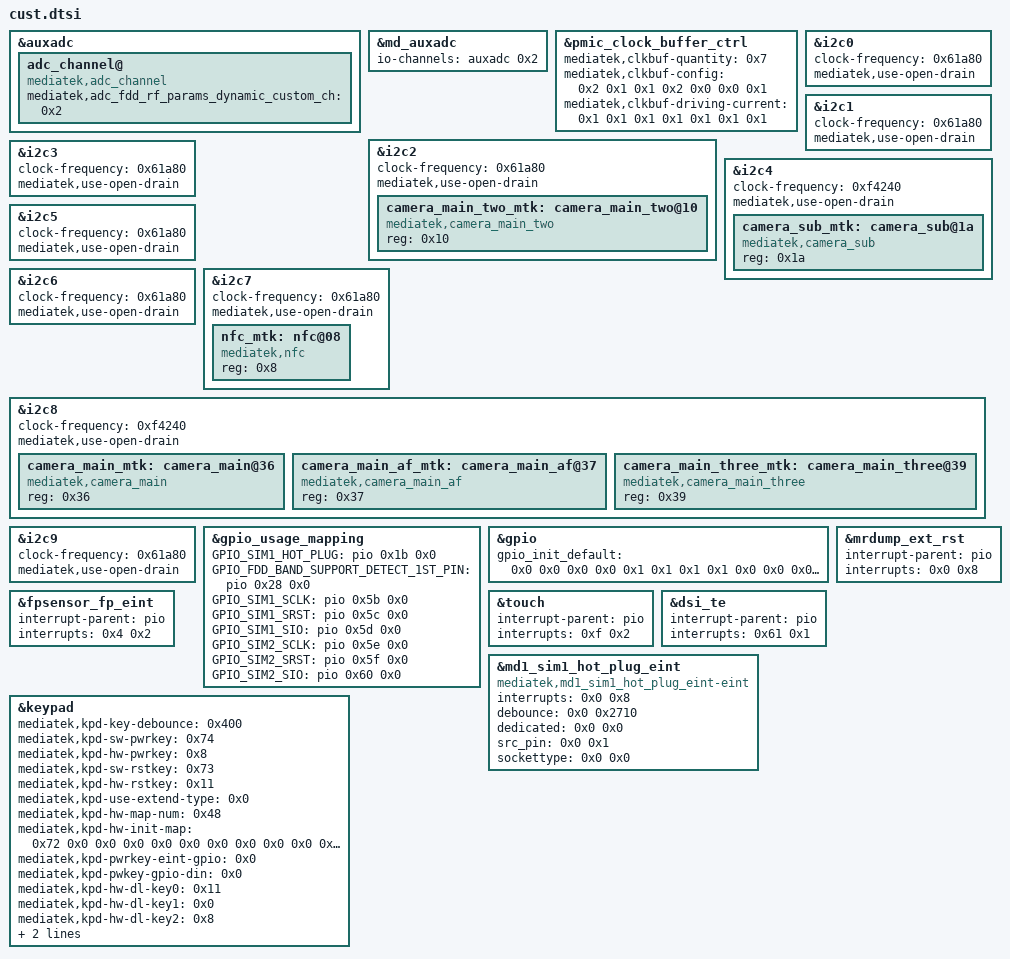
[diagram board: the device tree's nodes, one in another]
// SPDX-License-Identifier: GPL-2.0-only
/* Redmi Note 12S (sea / mt6781) DCT Custom Peripheral & EINT/I2C/GPIO Pinmux bindings for Kernel 6.6 */

&auxadc {
    adc_channel@ {
        compatible = "mediatek,adc_channel";
        mediatek,adc_fdd_rf_params_dynamic_custom_ch = <0x2>;
        status = "okay";
    };
};

&md_auxadc {
    io-channels = <&auxadc 0x2>;
};

&pmic_clock_buffer_ctrl {
    mediatek,clkbuf-quantity = <0x7>;
    mediatek,clkbuf-config = <0x2 0x1 0x1 0x2 0x0 0x0 0x1>;
    mediatek,clkbuf-driving-current = <0x1 0x1 0x1 0x1 0x1 0x1 0x1>;
    status = "okay";
};

&i2c0 {
    #address-cells = <0x1>;
    #size-cells = <0x0>;
    clock-frequency = <0x61a80>;
    mediatek,use-open-drain;
};

&i2c1 {
    #address-cells = <0x1>;
    #size-cells = <0x0>;
    clock-frequency = <0x61a80>;
    mediatek,use-open-drain;
};

&i2c2 {
    #address-cells = <0x1>;
    #size-cells = <0x0>;
    clock-frequency = <0x61a80>;
    mediatek,use-open-drain;
    camera_main_two_mtk: camera_main_two@10 {
        compatible = "mediatek,camera_main_two";
        reg = <0x10>;
        status = "okay";
    };
};

&i2c3 {
    #address-cells = <0x1>;
    #size-cells = <0x0>;
    clock-frequency = <0x61a80>;
    mediatek,use-open-drain;
};

&i2c4 {
    #address-cells = <0x1>;
    #size-cells = <0x0>;
    clock-frequency = <0xf4240>;
    mediatek,use-open-drain;
    camera_sub_mtk: camera_sub@1a {
        compatible = "mediatek,camera_sub";
        reg = <0x1a>;
        status = "okay";
    };
};

&i2c5 {
    #address-cells = <0x1>;
    #size-cells = <0x0>;
    clock-frequency = <0x61a80>;
    mediatek,use-open-drain;
};

&i2c6 {
    #address-cells = <0x1>;
    #size-cells = <0x0>;
    clock-frequency = <0x61a80>;
    mediatek,use-open-drain;
};

&i2c7 {
    #address-cells = <0x1>;
    #size-cells = <0x0>;
    clock-frequency = <0x61a80>;
    mediatek,use-open-drain;
    nfc_mtk: nfc@08 {
        compatible = "mediatek,nfc";
        reg = <0x8>;
        status = "okay";
    };
};

&i2c8 {
    #address-cells = <0x1>;
    #size-cells = <0x0>;
    clock-frequency = <0xf4240>;
    mediatek,use-open-drain;
    camera_main_mtk: camera_main@36 {
        compatible = "mediatek,camera_main";
        reg = <0x36>;
        status = "okay";
    };
    camera_main_af_mtk: camera_main_af@37 {
        compatible = "mediatek,camera_main_af";
        reg = <0x37>;
        status = "okay";
    };
    camera_main_three_mtk: camera_main_three@39 {
        compatible = "mediatek,camera_main_three";
        reg = <0x39>;
        status = "okay";
    };
};

&i2c9 {
    #address-cells = <0x1>;
    #size-cells = <0x0>;
    clock-frequency = <0x61a80>;
    mediatek,use-open-drain;
};

&gpio_usage_mapping {
    GPIO_SIM1_HOT_PLUG = <&pio 0x1b 0x0>;
    GPIO_FDD_BAND_SUPPORT_DETECT_1ST_PIN = <&pio 0x28 0x0>;
    GPIO_SIM1_SCLK = <&pio 0x5b 0x0>;
    GPIO_SIM1_SRST = <&pio 0x5c 0x0>;
    GPIO_SIM1_SIO = <&pio 0x5d 0x0>;
    GPIO_SIM2_SCLK = <&pio 0x5e 0x0>;
    GPIO_SIM2_SRST = <&pio 0x5f 0x0>;
    GPIO_SIM2_SIO = <&pio 0x60 0x0>;
};

&gpio {
    gpio_init_default = <0x0 0x0 0x0 0x0 0x1 0x1 0x1 0x1 0x0 0x0 0x0 0x1 0x0 0x1 0x2 0x0 0x0 0x0 0x1 0x0 0x1 0x3 0x0 0x1 0x0 0x1 0x0 0x1 0x4 0x0 0x0 0x0 0x1 0x1 0x1 0x5 0x0 0x0 0x0 0x1 0x0 0x1 0x6 0x0 0x0 0x0 0x1 0x1 0x1 0x7 0x0 0x1 0x0 0x1 0x0 0x0 0x8 0x0 0x1 0x0 0x1 0x0 0x1 0x9 0x0 0x0 0x0 0x1 0x1 0x1 0xa 0x0 0x0 0x0 0x1 0x0 0x1 0xb 0x0 0x0 0x0 0x1 0x1 0x1 0xc 0x0 0x0 0x0 0x1 0x0 0x1 0xd 0x2 0x0 0x0 0x0 0x0 0x0 0xe 0x0 0x0 0x0 0x1 0x1 0x1 0xf 0x0 0x0 0x0 0x1 0x1 0x1 0x10 0x0 0x1 0x0 0x1 0x0 0x1 0x11 0x0 0x0 0x0 0x1 0x0 0x0 0x12 0x0 0x1 0x0 0x1 0x0 0x0 0x13 0x0 0x1 0x0 0x1 0x0 0x0 0x14 0x0 0x1 0x0 0x1 0x0 0x0 0x15 0x0 0x1 0x1 0x1 0x0 0x0 0x16 0x0 0x1 0x0 0x1 0x0 0x0 0x17 0x0 0x1 0x0 0x1 0x0 0x0 0x18 0x0 0x1 0x0 0x1 0x0 0x0 0x19 0x0 0x1 0x0 0x1 0x0 0x0 0x1a 0x0 0x1 0x0 0x1 0x0 0x0 0x1b 0x1 0x0 0x0 0x1 0x1 0x0 0x1c 0x0 0x0 0x0 0x1 0x0 0x0 0x1d 0x0 0x1 0x0 0x1 0x0 0x0 0x1e 0x0 0x1 0x0 0x1 0x0 0x0 0x1f 0x0 0x0 0x0 0x1 0x0 0x1 0x20 0x1 0x0 0x0 0x1 0x1 0x0 0x21 0x1 0x0 0x0 0x0 0x0 0x0 0x22 0x1 0x0 0x0 0x1 0x1 0x1 0x23 0x1 0x0 0x0 0x0 0x0 0x1 0x24 0x1 0x0 0x0 0x0 0x0 0x0 0x25 0x1 0x0 0x0 0x0 0x0 0x0 0x26 0x1 0x0 0x0 0x0 0x0 0x0 0x27 0x1 0x0 0x0 0x1 0x0 0x0 0x28 0x0 0x0 0x0 0x0 0x0 0x0 0x29 0x0 0x1 0x0 0x1 0x0 0x0 0x2a 0x1 0x0 0x0 0x0 0x0 0x0 0x2b 0x1 0x0 0x0 0x1 0x0 0x0 0x2c 0x2 0x0 0x0 0x0 0x0 0x0 0x2d 0x2 0x0 0x0 0x0 0x0 0x1 0x2e 0x2 0x0 0x0 0x0 0x0 0x0 0x2f 0x2 0x0 0x0 0x1 0x0 0x1 0x30 0x4 0x0 0x0 0x1 0x1 0x0 0x31 0x4 0x0 0x0 0x0 0x0 0x0 0x32 0x1 0x0 0x0 0x0 0x0 0x0 0x33 0x4 0x0 0x0 0x0 0x0 0x0 0x34 0x6 0x0 0x0 0x1 0x0 0x0 0x35 0x6 0x0 0x0 0x1 0x0 0x0 0x36 0x6 0x0 0x0 0x0 0x0 0x0 0x37 0x6 0x0 0x0 0x1 0x0 0x0 0x38 0x0 0x1 0x0 0x1 0x0 0x0 0x39 0x2 0x0 0x0 0x0 0x0 0x1 0x3a 0x2 0x0 0x0 0x0 0x0 0x1 0x3b 0x2 0x0 0x0 0x1 0x0 0x1 0x3c 0x3 0x0 0x0 0x1 0x0 0x0 0x3d 0x6 0x0 0x0 0x1 0x0 0x0 0x3e 0x6 0x0 0x0 0x1 0x1 0x0 0x3f 0x6 0x0 0x0 0x1 0x0 0x0 0x40 0x6 0x0 0x0 0x1 0x0 0x0 0x41 0x6 0x0 0x0 0x1 0x0 0x0 0x42 0x6 0x0 0x0 0x1 0x0 0x0 0x43 0x6 0x0 0x0 0x1 0x0 0x0 0x50 0x1 0x0 0x0 0x1 0x1 0x1 0x51 0x0 0x1 0x0 0x1 0x0 0x1 0x52 0x3 0x0 0x0 0x1 0x0 0x1 0x53 0x0 0x0 0x0 0x1 0x1 0x1 0x55 0x1 0x0 0x0 0x1 0x0 0x1 0x56 0x1 0x0 0x0 0x1 0x0 0x1 0x57 0x1 0x0 0x0 0x1 0x0 0x1 0x58 0x1 0x0 0x0 0x1 0x0 0x1 0x59 0x1 0x0 0x0 0x1 0x0 0x1 0x5a 0x1 0x0 0x0 0x1 0x0 0x1 0x5b 0x1 0x0 0x0 0x0 0x0 0x1 0x5c 0x1 0x0 0x0 0x0 0x0 0x1 0x5d 0x1 0x0 0x0 0x1 0x1 0x1 0x5e 0x1 0x0 0x0 0x0 0x0 0x1 0x5f 0x1 0x0 0x0 0x0 0x0 0x1 0x60 0x1 0x0 0x0 0x1 0x1 0x1 0x61 0x1 0x0 0x0 0x1 0x0 0x0 0x62 0x0 0x1 0x0 0x1 0x0 0x0 0x63 0x1 0x0 0x0 0x0 0x0 0x0 0x64 0x1 0x0 0x0 0x1 0x0 0x0 0x65 0x1 0x0 0x0 0x1 0x0 0x0 0x66 0x1 0x0 0x0 0x1 0x0 0x0 0x67 0x1 0x0 0x0 0x1 0x0 0x0 0x68 0x1 0x0 0x0 0x1 0x0 0x0 0x69 0x1 0x0 0x0 0x1 0x0 0x0 0x6a 0x1 0x0 0x0 0x1 0x0 0x0 0x6b 0x1 0x0 0x0 0x1 0x0 0x0 0x6c 0x1 0x0 0x0 0x1 0x0 0x1 0x6d 0x1 0x0 0x0 0x1 0x0 0x1 0x6e 0x1 0x0 0x0 0x1 0x0 0x1 0x6f 0x1 0x0 0x0 0x1 0x0 0x1 0x70 0x1 0x0 0x0 0x1 0x0 0x1 0x71 0x1 0x0 0x0 0x1 0x0 0x1 0x72 0x1 0x0 0x0 0x1 0x0 0x1 0x73 0x1 0x0 0x0 0x1 0x0 0x1 0x74 0x1 0x0 0x0 0x1 0x0 0x1 0x75 0x1 0x0 0x0 0x1 0x0 0x0 0x76 0x1 0x0 0x0 0x1 0x0 0x0 0x77 0x1 0x0 0x0 0x1 0x0 0x0 0x78 0x1 0x0 0x0 0x1 0x0 0x0 0x79 0x1 0x0 0x0 0x1 0x0 0x1 0x7a 0x1 0x0 0x0 0x1 0x0 0x1 0x7b 0x1 0x0 0x0 0x1 0x0 0x1 0x7c 0x1 0x0 0x0 0x1 0x0 0x0 0x7d 0x1 0x0 0x0 0x1 0x0 0x1 0x7e 0x1 0x0 0x0 0x1 0x0 0x0 0x7f 0x1 0x0 0x0 0x1 0x0 0x0 0x80 0x1 0x0 0x0 0x1 0x0 0x0 0x81 0x1 0x0 0x0 0x1 0x0 0x0 0x82 0x1 0x0 0x0 0x1 0x0 0x0 0x83 0x1 0x0 0x0 0x1 0x0 0x0 0x84 0x1 0x0 0x0 0x1 0x0 0x0 0x85 0x1 0x0 0x0 0x1 0x0 0x0 0x86 0x1 0x0 0x0 0x1 0x0 0x0 0x87 0x1 0x0 0x0 0x1 0x0 0x0 0x88 0x1 0x0 0x0 0x1 0x0 0x0 0x89 0x1 0x0 0x0 0x1 0x0 0x0 0x8a 0x1 0x0 0x0 0x1 0x0 0x0 0x8b 0x1 0x0 0x0 0x1 0x0 0x0 0x8c 0x1 0x0 0x0 0x1 0x0 0x0 0x8d 0x1 0x0 0x0 0x1 0x0 0x0 0x8e 0x1 0x0 0x0 0x1 0x0 0x0 0x8f 0x1 0x0 0x0 0x1 0x0 0x0 0x90 0x1 0x0 0x0 0x1 0x1 0x1 0x91 0x1 0x0 0x0 0x1 0x1 0x1 0x92 0x2 0x0 0x0 0x1 0x1 0x1 0x93 0x2 0x0 0x0 0x1 0x1 0x1 0x94 0x1 0x0 0x0 0x1 0x1 0x1 0x95 0x1 0x0 0x0 0x1 0x1 0x1 0x96 0x3 0x0 0x0 0x1 0x1 0x1 0x97 0x3 0x0 0x0 0x1 0x1 0x1 0x98 0x1 0x0 0x0 0x1 0x1 0x1 0x99 0x1 0x0 0x0 0x1 0x1 0x1 0x9a 0x1 0x0 0x0 0x1 0x1 0x1 0x9b 0x1 0x0 0x0 0x1 0x1 0x1 0x9c 0x1 0x0 0x0 0x1 0x1 0x1 0x9d 0x1 0x0 0x0 0x1 0x1 0x1 0x9e 0x1 0x0 0x0 0x1 0x1 0x1 0x9f 0x1 0x0 0x0 0x1 0x1 0x1 0xa0 0x1 0x0 0x0 0x1 0x1 0x1 0xa1 0x1 0x0 0x0 0x1 0x1 0x1 0xa2 0x1 0x0 0x0 0x1 0x1 0x1 0xa3 0x1 0x0 0x0 0x1 0x1 0x1 0xa4 0x0 0x1 0x1 0x1 0x0 0x1 0xa5 0x0 0x1 0x1 0x1 0x0 0x1 0xa6 0x0 0x1 0x0 0x1 0x0 0x1 0xa7 0x0 0x1 0x0 0x1 0x0 0x1 0xa8 0x0 0x1 0x0 0x1 0x0 0x1 0xa9 0x0 0x1 0x0 0x1 0x0 0x1 0xaa 0x0 0x1 0x0 0x1 0x0 0x1 0xab 0x0 0x1 0x0 0x1 0x0 0x1 0xac 0x2 0x0 0x0 0x1 0x0 0x1 0xad 0x2 0x0 0x0 0x1 0x0 0x1 0xae 0x1 0x0 0x0 0x0 0x0 0x1 0xaf 0x1 0x0 0x0 0x0 0x0 0x1 0xb0 0x1 0x0 0x0 0x1 0x0 0x1 0xb1 0x1 0x0 0x0 0x1 0x0 0x1 0xb2 0x1 0x0 0x0 0x0 0x0 0x0 0xb3 0x1 0x0 0x0 0x0 0x0 0x0 0xb4 0x1 0x0 0x0 0x0 0x0 0x1 0xb5 0x1 0x0 0x0 0x1 0x0 0x1 0xb6 0x1 0x0 0x0 0x0 0x0 0x0 0xb7 0x1 0x0 0x0 0x0 0x0 0x1 0xb8 0x1 0x0 0x0 0x0 0x0 0x1 0xb9 0x1 0x0 0x0 0x0 0x0 0x1 0xba 0x1 0x0 0x0 0x0 0x0 0x1 0xbb 0x1 0x0 0x0 0x1 0x0 0x1 0xbc 0x1 0x0 0x0 0x1 0x0 0x1 0xbd 0x1 0x0 0x0 0x1 0x0 0x1 0xbe 0x1 0x0 0x0 0x1 0x0 0x1 0xbf 0x0 0x0 0x0 0x1 0x0 0x0 0xc0 0x0 0x0 0x0 0x1 0x0 0x0 0xc1 0x0 0x0 0x0 0x1 0x0 0x0 0xc2 0x0 0x0 0x0 0x1 0x0 0x0 0xc3 0x0 0x0 0x0 0x1 0x0 0x0 0xc4 0x0 0x0 0x0 0x1 0x0 0x0 0xc5 0x0 0x0 0x0 0x1 0x0 0x0 0xc6 0x0 0x0 0x0 0x1 0x0 0x0 0xc7 0x0 0x0 0x0 0x1 0x0 0x0 0xc8 0x0 0x0 0x0 0x1 0x0 0x0 0xc9 0x0 0x0 0x0 0x1 0x0 0x0 0xca 0x0 0x0 0x0 0x1 0x0 0x0 0xcb 0x0 0x0 0x0 0x1 0x0 0x0 0xcc 0x0 0x0 0x0 0x1 0x0 0x0 0xcd 0x0 0x0 0x0 0x1 0x0 0x0 0xce 0x0 0x0 0x0 0x1 0x0 0x0 0xcf 0x0 0x0 0x0 0x1 0x0 0x0 0xd0 0x0 0x0 0x0 0x1 0x0 0x0 0xd1 0x0 0x0 0x0 0x1 0x0 0x0 0xd2 0x0 0x0 0x0 0x1 0x0 0x0 0xd3 0x0 0x0 0x0 0x1 0x0 0x0 0xd4 0x0 0x0 0x0 0x1 0x0 0x0 0xd5 0x0 0x0 0x0 0x1 0x0 0x0 0xd6 0x0 0x0 0x0 0x1 0x0 0x0 0xd7 0x0 0x0 0x0 0x1 0x0 0x0 0xd8 0x0 0x0 0x0 0x1 0x0 0x0 0xd9 0x0 0x0 0x0 0x1 0x0 0x0 0xda 0x0 0x0 0x0 0x1 0x0 0x0 0xdb 0x0 0x0 0x0 0x1 0x0 0x0 0xdc 0x0 0x0 0x0 0x1 0x0 0x0 0xdd 0x0 0x0 0x0 0x1 0x0 0x0>;
};

&mrdump_ext_rst {
    interrupt-parent = <&pio>;
    interrupts = <0x0 0x8>;
    status = "okay";
};

&fpsensor_fp_eint {
    interrupt-parent = <&pio>;
    interrupts = <0x4 0x2>;
    status = "okay";
};

&touch {
    interrupt-parent = <&pio>;
    interrupts = <0xf 0x2>;
    status = "okay";
};

&dsi_te {
    interrupt-parent = <&pio>;
    interrupts = <0x61 0x1>;
    status = "okay";
};

&md1_sim1_hot_plug_eint {
    compatible = "mediatek,md1_sim1_hot_plug_eint-eint";
    interrupts = <0x0 0x8>;
    debounce = <0x0 0x2710>;
    dedicated = <0x0 0x0>;
    src_pin = <0x0 0x1>;
    sockettype = <0x0 0x0>;
    status = "okay";
};

&keypad {
    mediatek,kpd-key-debounce = <0x400>;
    mediatek,kpd-sw-pwrkey = <0x74>;
    mediatek,kpd-hw-pwrkey = <0x8>;
    mediatek,kpd-sw-rstkey = <0x73>;
    mediatek,kpd-hw-rstkey = <0x11>;
    mediatek,kpd-use-extend-type = <0x0>;
    mediatek,kpd-hw-map-num = <0x48>;
    mediatek,kpd-hw-init-map = <0x72 0x0 0x0 0x0 0x0 0x0 0x0 0x0 0x0 0x0 0x0 0x0 0x0 0x0 0x0 0x0 0x0 0x0 0x0 0x0 0x0 0x0 0x0 0x0 0x0 0x0 0x0 0x0 0x0 0x0 0x0 0x0 0x0 0x0 0x0 0x0 0x0 0x0 0x0 0x0 0x0 0x0 0x0 0x0 0x0 0x0 0x0 0x0 0x0 0x0 0x0 0x0 0x0 0x0 0x0 0x0 0x0 0x0 0x0 0x0 0x0 0x0 0x0 0x0 0x0 0x0 0x0 0x0 0x0 0x0 0x0 0x0>;
    mediatek,kpd-pwrkey-eint-gpio = <0x0>;
    mediatek,kpd-pwkey-gpio-din = <0x0>;
    mediatek,kpd-hw-dl-key0 = <0x11>;
    mediatek,kpd-hw-dl-key1 = <0x0>;
    mediatek,kpd-hw-dl-key2 = <0x8>;
    mediatek,kpd-hw-recovery-key = <0x11>;
    mediatek,kpd-hw-factory-key = <0x0>;
    status = "okay";
};
